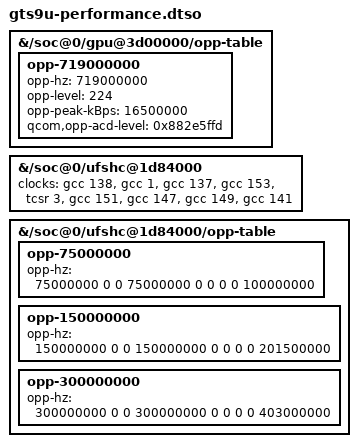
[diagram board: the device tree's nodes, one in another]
// SPDX-License-Identifier: BSD-3-Clause
/dts-v1/;
/plugin/;

/*
 * Ultra-only additions, applied by Linux before DRM probes, never by Samsung
 * ABL.  The prime-CPU boost OPP that every family board needs lives in
 * gts9-performance.dtso.  719 MHz is the top of Samsung's GPU bin 0, which
 * kgsl selects by SoC feature code (AC, AF and internal parts); it stays here
 * until another board's unit is confirmed to be that bin.
 *
 * The UFS inline crypto engine sits in the data path of every UFS transfer,
 * encrypted or not, and the bootloader leaves its core clock at XO: at
 * 19.2 MHz it caps all UFS I/O near 300 MB/s.  Fragments 1 and 2 list it
 * with the controller's clocks so the UFS OPPs scale it, at the corners of
 * Samsung's gcc-kalama.c (rate_max 100 MHz at VDD_LOWER, 201.5 MHz at
 * VDD_LOW, 403 MHz at VDD_NOMINAL).  The SM-X710 has the same change in its
 * board DTS, where it measured 1.84 GB/s read and 1.6 GB/s write.
 *
 * Voltage: the OPPs' CX levels reach no rail (&gcc has no power-domains, so
 * UFS_PHY_GDSC has no parent), as with mainline's own 300 MHz UFS clocks.
 * 403 MHz is covered only because rpmhpd has not synced on this board and
 * holds CX at its maximum.  The UFS needs a real CX vote before it syncs.
 *
 * No preprocessor runs on this file, so the clock IDs are numbers: those of
 * dt-bindings/clock/qcom,sm8550-gcc.h and qcom,sm8550-tcsr.h.
 */
/ {
	fragment@0 {
		target-path = "/soc@0/gpu@3d00000/opp-table";
		__overlay__ {
			opp-719000000 {
				opp-hz = /bits/ 64 <719000000>;
				/* RPMH_REGULATOR_LEVEL_SVS_L2, Samsung X910 bin 0. */
				opp-level = <224>;
				opp-peak-kBps = <16500000>;
				qcom,opp-acd-level = <0x882e5ffd>;
			};
		};
	};

	fragment@1 {
		target-path = "/soc@0/ufshc@1d84000";
		__overlay__ {
			clocks = <&gcc 138>,	/* GCC_UFS_PHY_AXI_CLK */
				 <&gcc 1>,	/* GCC_AGGRE_UFS_PHY_AXI_CLK */
				 <&gcc 137>,	/* GCC_UFS_PHY_AHB_CLK */
				 <&gcc 153>,	/* GCC_UFS_PHY_UNIPRO_CORE_CLK */
				 <&tcsr 3>,	/* TCSR_UFS_PAD_CLKREF_EN */
				 <&gcc 151>,	/* GCC_UFS_PHY_TX_SYMBOL_0_CLK */
				 <&gcc 147>,	/* GCC_UFS_PHY_RX_SYMBOL_0_CLK */
				 <&gcc 149>,	/* GCC_UFS_PHY_RX_SYMBOL_1_CLK */
				 <&gcc 141>;	/* GCC_UFS_PHY_ICE_CORE_CLK */
			clock-names = "core_clk",
				      "bus_aggr_clk",
				      "iface_clk",
				      "core_clk_unipro",
				      "ref_clk",
				      "tx_lane0_sync_clk",
				      "rx_lane0_sync_clk",
				      "rx_lane1_sync_clk",
				      "ice_core_clk";
		};
	};

	fragment@2 {
		target-path = "/soc@0/ufshc@1d84000/opp-table";
		__overlay__ {
			opp-75000000 {
				opp-hz = /bits/ 64 <75000000 0 0 75000000 0 0 0 0
						    100000000>;
			};

			opp-150000000 {
				opp-hz = /bits/ 64 <150000000 0 0 150000000 0 0 0 0
						    201500000>;
			};

			opp-300000000 {
				opp-hz = /bits/ 64 <300000000 0 0 300000000 0 0 0 0
						    403000000>;
			};
		};
	};
};
